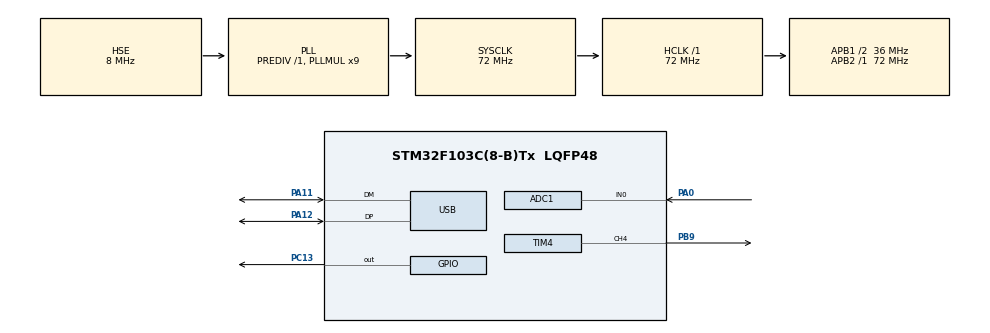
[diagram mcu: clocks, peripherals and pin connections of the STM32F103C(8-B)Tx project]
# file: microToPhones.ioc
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ADC1.Channel-2\#ChannelRegularConversion=ADC_CHANNEL_0
ADC1.DataAlign=ADC_DATAALIGN_LEFT
ADC1.ExternalTrigConv=ADC_EXTERNALTRIGCONV_T3_TRGO
ADC1.NbrOfConversionFlag=1
ADC1.Rank-2\#ChannelRegularConversion=1
ADC1.SamplingTime-2\#ChannelRegularConversion=ADC_SAMPLETIME_41CYCLES_5
ADC1.master=1
Mcu.Family=STM32F1
Mcu.Name=STM32F103C(8-B)Tx
Mcu.Package=LQFP48
NVIC.ADC1_2_IRQn=true\:0\:0\:false\:false\:true\:true\:true
NVIC.PriorityGroup=NVIC_PRIORITYGROUP_4
NVIC.TIM3_IRQn=true\:0\:0\:false\:false\:true\:true\:true
NVIC.USB_LP_CAN1_RX0_IRQn=true\:0\:0\:false\:false\:true\:false\:true
PA0-WKUP.Signal=ADCx_IN0
PA11.Mode=Device
PA11.Signal=USB_DM
PA12.Mode=Device
PA12.Signal=USB_DP
PA13.Mode=Serial_Wire
PA13.Signal=SYS_JTMS-SWDIO
PA14.Mode=Serial_Wire
PA14.Signal=SYS_JTCK-SWCLK
PB9.Signal=S_TIM4_CH4
PC13-TAMPER-RTC.Signal=GPIO_Output
PD0-OSC_IN.Mode=HSE-External-Oscillator
PD0-OSC_IN.Signal=RCC_OSC_IN
PD1-OSC_OUT.Mode=HSE-External-Oscillator
PD1-OSC_OUT.Signal=RCC_OSC_OUT
ProjectManager.HeapSize=0x200
ProjectManager.StackSize=0x400
ProjectManager.TargetToolchain=STM32CubeIDE
RCC.ADCPresc=RCC_ADCPCLK2_DIV6
RCC.AHBFreq_Value=72000000
RCC.APB1CLKDivider=RCC_HCLK_DIV2
RCC.APB1Freq_Value=36000000
RCC.APB1TimFreq_Value=72000000
RCC.APB2Freq_Value=72000000
RCC.APB2TimFreq_Value=72000000
RCC.HCLKFreq_Value=72000000
RCC.PLLMUL=RCC_PLL_MUL9
RCC.PLLSourceVirtual=RCC_PLLSOURCE_HSE
RCC.SYSCLKFreq_VALUE=72000000
RCC.SYSCLKSource=RCC_SYSCLKSOURCE_PLLCLK
RCC.USBFreq_Value=48000000
RCC.USBPrescaler=RCC_USBCLKSOURCE_PLL_DIV1_5
SH.ADCx_IN0.0=ADC1_IN0,IN0
SH.S_TIM4_CH4.0=TIM4_CH4,PWM Generation4 CH4
TIM3.Period=500-1
TIM3.Prescaler=8-1
TIM3.TIM_MasterOutputTrigger=TIM_TRGO_UPDATE
TIM4.Channel-PWM\ Generation4\ CH4=TIM_CHANNEL_4
TIM4.Period=500-1
TIM4.Prescaler=8-1
TIM4.Pulse-PWM\ Generation4\ CH4=100
USB_DEVICE.CLASS_NAME_FS=CDC
USB_DEVICE.VirtualMode=Cdc
USB_DEVICE.VirtualModeFS=Cdc_FS
VP_TIM3_VS_ClockSourceINT.Mode=Internal
VP_TIM4_VS_ClockSourceINT.Mode=Internal
VP_USB_DEVICE_VS_USB_DEVICE_CDC_FS.Mode=CDC_FS
board=custom

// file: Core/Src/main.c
/* USER CODE BEGIN Header */
/**
  ******************************************************************************
  * @file           : main.c
  * @brief          : Main program body
  ******************************************************************************
  * @attention
  *
  * <h2><center>&copy; Copyright (c) 2020 STMicroelectronics.
  * All rights reserved.</center></h2>
  *
  * This software component is licensed by ST under BSD 3-Clause license,
  * the "License"; You may not use this file except in compliance with the
  * License. You may obtain a copy of the License at:
  *                        opensource.org/licenses/BSD-3-Clause
  *
  ******************************************************************************
  */
/* USER CODE END Header */
#include "main.h"
#include "usb_device.h"

ADC_HandleTypeDef hadc1;

TIM_HandleTypeDef htim3;
TIM_HandleTypeDef htim4;

void SystemClock_Config(void);
static void MX_GPIO_Init(void);
static void MX_ADC1_Init(void);
static void MX_TIM4_Init(void);
static void MX_TIM3_Init(void);
/* USER CODE BEGIN PFP */

volatile uint8_t cnt;

/* USER CODE END PFP */

int main(void)
{

  /* MCU Configuration--------------------------------------------------------*/

  /* Reset of all peripherals, Initializes the Flash interface and the Systick. */
  HAL_Init();

  /* Configure the system clock */
  SystemClock_Config();

  /* Initialize all configured peripherals */
  MX_GPIO_Init();
  MX_ADC1_Init();
  MX_TIM4_Init();
  MX_TIM3_Init();
  MX_USB_DEVICE_Init();
  /* USER CODE BEGIN 2 */
  HAL_TIM_Base_Start_IT(&htim3);
  HAL_TIM_PWM_Start(&htim4, TIM_CHANNEL_4);
  HAL_ADC_Start(&hadc1);

  cnt = 0;

  /* USER CODE END 2 */

  /* Infinite loop */
  while (1)
  {

    /* USER CODE BEGIN 3 */
//	  CDC_Transmit_FS("hello", 5);
//	  HAL_Delay(333);
  }
  /* USER CODE END 3 */
}

void SystemClock_Config(void)
{
  RCC_OscInitTypeDef RCC_OscInitStruct = {0};
  RCC_ClkInitTypeDef RCC_ClkInitStruct = {0};
  RCC_PeriphCLKInitTypeDef PeriphClkInit = {0};

  /** Initializes the RCC Oscillators according to the specified parameters
  * in the RCC_OscInitTypeDef structure.
  */
  RCC_OscInitStruct.OscillatorType = RCC_OSCILLATORTYPE_HSE;
  RCC_OscInitStruct.HSEState = RCC_HSE_ON;
  RCC_OscInitStruct.HSEPredivValue = RCC_HSE_PREDIV_DIV1;
  RCC_OscInitStruct.HSIState = RCC_HSI_ON;
  RCC_OscInitStruct.PLL.PLLState = RCC_PLL_ON;
  RCC_OscInitStruct.PLL.PLLSource = RCC_PLLSOURCE_HSE;
  RCC_OscInitStruct.PLL.PLLMUL = RCC_PLL_MUL9;
  if (HAL_RCC_OscConfig(&RCC_OscInitStruct) != HAL_OK)
  {
    Error_Handler();
  }
  /** Initializes the CPU, AHB and APB buses clocks
  */
  RCC_ClkInitStruct.ClockType = RCC_CLOCKTYPE_HCLK|RCC_CLOCKTYPE_SYSCLK
                              |RCC_CLOCKTYPE_PCLK1|RCC_CLOCKTYPE_PCLK2;
  RCC_ClkInitStruct.SYSCLKSource = RCC_SYSCLKSOURCE_PLLCLK;
  RCC_ClkInitStruct.AHBCLKDivider = RCC_SYSCLK_DIV1;
  RCC_ClkInitStruct.APB1CLKDivider = RCC_HCLK_DIV2;
  RCC_ClkInitStruct.APB2CLKDivider = RCC_HCLK_DIV1;

  if (HAL_RCC_ClockConfig(&RCC_ClkInitStruct, FLASH_LATENCY_2) != HAL_OK)
  {
    Error_Handler();
  }
  PeriphClkInit.PeriphClockSelection = RCC_PERIPHCLK_ADC|RCC_PERIPHCLK_USB;
  PeriphClkInit.AdcClockSelection = RCC_ADCPCLK2_DIV6;
  PeriphClkInit.UsbClockSelection = RCC_USBCLKSOURCE_PLL_DIV1_5;
  if (HAL_RCCEx_PeriphCLKConfig(&PeriphClkInit) != HAL_OK)
  {
    Error_Handler();
  }
}

static void MX_ADC1_Init(void)
{

  ADC_ChannelConfTypeDef sConfig = {0};

  /** Common config
  */
  hadc1.Instance = ADC1;
  hadc1.Init.ScanConvMode = ADC_SCAN_DISABLE;
  hadc1.Init.ContinuousConvMode = DISABLE;
  hadc1.Init.DiscontinuousConvMode = DISABLE;
  hadc1.Init.ExternalTrigConv = ADC_EXTERNALTRIGCONV_T3_TRGO;
  hadc1.Init.DataAlign = ADC_DATAALIGN_LEFT;
  hadc1.Init.NbrOfConversion = 1;
  if (HAL_ADC_Init(&hadc1) != HAL_OK)
  {
    Error_Handler();
  }
  /** Configure Regular Channel
  */
  sConfig.Channel = ADC_CHANNEL_0;
  sConfig.Rank = ADC_REGULAR_RANK_1;
  sConfig.SamplingTime = ADC_SAMPLETIME_41CYCLES_5;
  if (HAL_ADC_ConfigChannel(&hadc1, &sConfig) != HAL_OK)
  {
    Error_Handler();
  }

}

static void MX_TIM3_Init(void)
{

  TIM_ClockConfigTypeDef sClockSourceConfig = {0};
  TIM_MasterConfigTypeDef sMasterConfig = {0};

  htim3.Instance = TIM3;
  htim3.Init.Prescaler = 8-1;
  htim3.Init.CounterMode = TIM_COUNTERMODE_UP;
  htim3.Init.Period = 500-1;
  htim3.Init.ClockDivision = TIM_CLOCKDIVISION_DIV1;
  htim3.Init.AutoReloadPreload = TIM_AUTORELOAD_PRELOAD_DISABLE;
  if (HAL_TIM_Base_Init(&htim3) != HAL_OK)
  {
    Error_Handler();
  }
  sClockSourceConfig.ClockSource = TIM_CLOCKSOURCE_INTERNAL;
  if (HAL_TIM_ConfigClockSource(&htim3, &sClockSourceConfig) != HAL_OK)
  {
    Error_Handler();
  }
  sMasterConfig.MasterOutputTrigger = TIM_TRGO_UPDATE;
  sMasterConfig.MasterSlaveMode = TIM_MASTERSLAVEMODE_DISABLE;
  if (HAL_TIMEx_MasterConfigSynchronization(&htim3, &sMasterConfig) != HAL_OK)
  {
    Error_Handler();
  }

}

static void MX_TIM4_Init(void)
{

  TIM_ClockConfigTypeDef sClockSourceConfig = {0};
  TIM_MasterConfigTypeDef sMasterConfig = {0};
  TIM_OC_InitTypeDef sConfigOC = {0};

  htim4.Instance = TIM4;
  htim4.Init.Prescaler = 8-1;
  htim4.Init.CounterMode = TIM_COUNTERMODE_UP;
  htim4.Init.Period = 500-1;
  htim4.Init.ClockDivision = TIM_CLOCKDIVISION_DIV1;
  htim4.Init.AutoReloadPreload = TIM_AUTORELOAD_PRELOAD_DISABLE;
  if (HAL_TIM_Base_Init(&htim4) != HAL_OK)
  {
    Error_Handler();
  }
  sClockSourceConfig.ClockSource = TIM_CLOCKSOURCE_INTERNAL;
  if (HAL_TIM_ConfigClockSource(&htim4, &sClockSourceConfig) != HAL_OK)
  {
    Error_Handler();
  }
  if (HAL_TIM_PWM_Init(&htim4) != HAL_OK)
  {
    Error_Handler();
  }
  sMasterConfig.MasterOutputTrigger = TIM_TRGO_RESET;
  sMasterConfig.MasterSlaveMode = TIM_MASTERSLAVEMODE_DISABLE;
  if (HAL_TIMEx_MasterConfigSynchronization(&htim4, &sMasterConfig) != HAL_OK)
  {
    Error_Handler();
  }
  sConfigOC.OCMode = TIM_OCMODE_PWM1;
  sConfigOC.Pulse = 100;
  sConfigOC.OCPolarity = TIM_OCPOLARITY_HIGH;
  sConfigOC.OCFastMode = TIM_OCFAST_DISABLE;
  if (HAL_TIM_PWM_ConfigChannel(&htim4, &sConfigOC, TIM_CHANNEL_4) != HAL_OK)
  {
    Error_Handler();
  }
  HAL_TIM_MspPostInit(&htim4);

}

static void MX_GPIO_Init(void)
{
  GPIO_InitTypeDef GPIO_InitStruct = {0};

  /* GPIO Ports Clock Enable */
  __HAL_RCC_GPIOC_CLK_ENABLE();
  __HAL_RCC_GPIOD_CLK_ENABLE();
  __HAL_RCC_GPIOA_CLK_ENABLE();
  __HAL_RCC_GPIOB_CLK_ENABLE();

  /*Configure GPIO pin Output Level */
  HAL_GPIO_WritePin(GPIOC, GPIO_PIN_13, GPIO_PIN_RESET);

  /*Configure GPIO pin : PC13 */
  GPIO_InitStruct.Pin = GPIO_PIN_13;
  GPIO_InitStruct.Mode = GPIO_MODE_OUTPUT_PP;
  GPIO_InitStruct.Pull = GPIO_NOPULL;
  GPIO_InitStruct.Speed = GPIO_SPEED_FREQ_LOW;
  HAL_GPIO_Init(GPIOC, &GPIO_InitStruct);

}

/* USER CODE BEGIN 4 */

HAL_TIM_PeriodElapsedCallback(TIM_HandleTypeDef *htim){
	HAL_GPIO_TogglePin(GPIOC, GPIO_PIN_13);
	uint8_t val = (ADC1->DR >> 8);
	uint8_t result = 0x7f + ((0x7f - val) << 2);
	TIM4->CCR4 = result;
	CDC_Transmit_FS(result, 1);
//	TIM4->CCR4 = cnt++;
}

/* USER CODE END 4 */

void Error_Handler(void)
{
}

/************************ (C) COPYRIGHT STMicroelectronics *****END OF FILE****/
